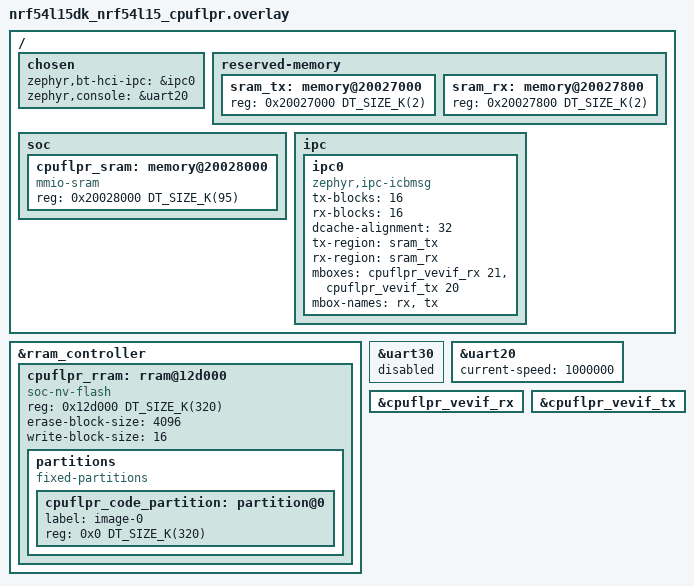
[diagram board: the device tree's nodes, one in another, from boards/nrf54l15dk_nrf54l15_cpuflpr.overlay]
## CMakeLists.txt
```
# SPDX-License-Identifier: Apache-2.0

cmake_minimum_required(VERSION 3.28.0)

find_package(Zephyr REQUIRED HINTS $ENV{ZEPHYR_BASE})
project(hci_ipc)

target_sources(app PRIVATE src/main.c)
```

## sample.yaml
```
sample:
  description: Allows Zephyr to provide Bluetooth connectivity via IPC
  name: Bluetooth HCI IPC
tests:
  sample.bluetooth.hci_ipc:
    harness: bluetooth
    tags: bluetooth
    platform_allow:
      - nrf5340dk/nrf5340/cpunet
      - nrf5340_audio_dk/nrf5340/cpunet
      - nrf5340bsim/nrf5340/cpunet
      - nrf54l15dk/nrf54l15/cpuflpr
    integration_platforms:
      - nrf5340dk/nrf5340/cpunet
      - nrf5340_audio_dk/nrf5340/cpunet
      - nrf54l15dk/nrf54l15/cpuflpr
  sample.bluetooth.hci_ipc.iso_broadcast.bt_ll_sw_split:
    harness: bluetooth
    tags: bluetooth
    extra_args: CONF_FILE="nrf5340_cpunet_iso_broadcast-bt_ll_sw_split.conf"
    platform_allow:
      - nrf5340dk/nrf5340/cpunet
      - nrf5340_audio_dk/nrf5340/cpunet
      - nrf5340bsim/nrf5340/cpunet
    integration_platforms:
      - nrf5340dk/nrf5340/cpunet
  sample.bluetooth.hci_ipc.iso_receive.bt_ll_sw_split:
    harness: bluetooth
    tags: bluetooth
    extra_args: CONF_FILE="nrf5340_cpunet_iso_receive-bt_ll_sw_split.conf"
    platform_allow:
      - nrf5340dk/nrf5340/cpunet
      - nrf5340_audio_dk/nrf5340/cpunet
      - nrf5340bsim/nrf5340/cpunet
    integration_platforms:
      - nrf5340dk/nrf5340/cpunet
  sample.bluetooth.hci_ipc.bis.bt_ll_sw_split:
    harness: bluetooth
    tags: bluetooth
    extra_args: CONF_FILE="nrf5340_cpunet_bis-bt_ll_sw_split.conf"
    platform_allow:
      - nrf5340dk/nrf5340/cpunet
      - nrf5340_audio_dk/nrf5340/cpunet
      - nrf5340bsim/nrf5340/cpunet
    integration_platforms:
      - nrf5340dk/nrf5340/cpunet
  sample.bluetooth.hci_ipc.iso_central.bt_ll_sw_split:
    harness: bluetooth
    tags: bluetooth
    extra_args: CONF_FILE="nrf5340_cpunet_iso_central-bt_ll_sw_split.conf"
    platform_allow:
      - nrf5340dk/nrf5340/cpunet
      - nrf5340_audio_dk/nrf5340/cpunet
      - nrf5340bsim/nrf5340/cpunet
    integration_platforms:
      - nrf5340dk/nrf5340/cpunet
  sample.bluetooth.hci_ipc.iso_peripheral.bt_ll_sw_split:
    harness: bluetooth
    tags: bluetooth
    extra_args: CONF_FILE="nrf5340_cpunet_iso_peripheral-bt_ll_sw_split.conf"
    platform_allow:
      - nrf5340dk/nrf5340/cpunet
      - nrf5340_audio_dk/nrf5340/cpunet
      - nrf5340bsim/nrf5340/cpunet
    integration_platforms:
      - nrf5340dk/nrf5340/cpunet
  sample.bluetooth.hci_ipc.cis.bt_ll_sw_split:
    harness: bluetooth
    tags: bluetooth
    extra_args: CONF_FILE="nrf5340_cpunet_cis-bt_ll_sw_split.conf"
    platform_allow:
      - nrf5340dk/nrf5340/cpunet
      - nrf5340_audio_dk/nrf5340/cpunet
      - nrf5340bsim/nrf5340/cpunet
    integration_platforms:
      - nrf5340dk/nrf5340/cpunet
  sample.bluetooth.hci_ipc.iso.bt_ll_sw_split:
    harness: bluetooth
    tags: bluetooth
    extra_args: CONF_FILE="nrf5340_cpunet_iso-bt_ll_sw_split.conf"
    platform_allow:
      - nrf5340dk/nrf5340/cpunet
      - nrf5340_audio_dk/nrf5340/cpunet
      - nrf5340bsim/nrf5340/cpunet
    integration_platforms:
      - nrf5340dk/nrf5340/cpunet
  sample.bluetooth.hci_ipc.iso.fem.bt_ll_sw_split:
    harness: bluetooth
    tags: bluetooth
    extra_args:
      - CONF_FILE="nrf5340_cpunet_iso-bt_ll_sw_split.conf"
      - EXTRA_CONF_FILE="overlay-nrf5340_cpunet_iso_nrf21540_ek-bt_ll_sw_split.conf"
      - DTC_OVERLAY_FILE="./boards/nrf5340_audio_dk_nrf5340_cpunet_nrf21540_ek.overlay"
    platform_allow:
      - nrf5340_audio_dk/nrf5340/cpunet
    integration_platforms:
      - nrf5340_audio_dk/nrf5340/cpunet
  sample.bluetooth.hci_ipc.df.bt_ll_sw_split:
    harness: bluetooth
    tags: bluetooth
    extra_args:
      - CONF_FILE="nrf5340_cpunet_df-bt_ll_sw_split.conf"
      - DTC_OVERLAY_FILE="nrf5340_cpunet_df-bt_ll_sw_split.overlay"
    platform_allow: nrf5340dk/nrf5340/cpunet
    integration_platforms:
      - nrf5340dk/nrf5340/cpunet
  sample.bluetooth.hci_ipc.df.no_phy_coded.bt_ll_sw_split:
    harness: bluetooth
    tags: bluetooth
    extra_args:
      - CONF_FILE="nrf5340_cpunet_df-bt_ll_sw_split.conf"
      - DTC_OVERLAY_FILE="nrf5340_cpunet_df-bt_ll_sw_split.overlay"
      - CONFIG_BT_CTLR_PHY_CODED=n
    platform_allow: nrf5340dk/nrf5340/cpunet
    integration_platforms:
      - nrf5340dk/nrf5340/cpunet
  sample.bluetooth.hci_ipc.mesh.bt_ll_sw_split:
    harness: bluetooth
    tags: bluetooth
    extra_args: CONF_FILE="nrf5340_cpunet_bt_mesh-bt_ll_sw_split.conf"
    platform_allow: nrf5340dk/nrf5340/cpunet
    integration_platforms:
      - nrf5340dk/nrf5340/cpunet
```

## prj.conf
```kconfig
CONFIG_IPC_SERVICE=y
CONFIG_MBOX=y

CONFIG_HEAP_MEM_POOL_SIZE=4096

CONFIG_MAIN_STACK_SIZE=512
CONFIG_SYSTEM_WORKQUEUE_STACK_MIN_SIZE_APP=512

CONFIG_BT=y
CONFIG_BT_HCI_RAW=y
CONFIG_BT_MAX_CONN=16

# Enable and adjust the below value as necessary to match Controller values
# CONFIG_BT_BUF_EVT_RX_COUNT=16
# CONFIG_BT_BUF_EVT_RX_SIZE=255
# CONFIG_BT_BUF_ACL_RX_SIZE=255
# CONFIG_BT_BUF_ACL_TX_SIZE=251
# CONFIG_BT_BUF_CMD_TX_SIZE=255
```

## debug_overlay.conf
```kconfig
CONFIG_LOG=y

CONFIG_ASSERT=y
CONFIG_EXCEPTION_STACK_TRACE=y
```

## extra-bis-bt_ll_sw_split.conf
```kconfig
# Zephyr Controller stack sizes across supported SoCs
CONFIG_ISR_STACK_SIZE=1536
CONFIG_IDLE_STACK_SIZE=256
CONFIG_MAIN_STACK_SIZE=512
CONFIG_SYSTEM_WORKQUEUE_STACK_SIZE=512
CONFIG_HEAP_MEM_POOL_SIZE=4096

# BT Buffers
CONFIG_BT_BUF_EVT_RX_COUNT=16
CONFIG_BT_BUF_EVT_RX_SIZE=255
CONFIG_BT_BUF_ACL_RX_SIZE=255
CONFIG_BT_BUF_ACL_TX_SIZE=251
CONFIG_BT_BUF_CMD_TX_SIZE=255

# Host and Controller common dependencies
CONFIG_BT_BROADCASTER=y
CONFIG_BT_OBSERVER=y
CONFIG_BT_EXT_ADV=y
CONFIG_BT_PER_ADV=y
CONFIG_BT_PER_ADV_SYNC=y
CONFIG_BT_PER_ADV_SYNC_MAX=2
CONFIG_BT_CENTRAL=y
CONFIG_BT_PERIPHERAL=y
CONFIG_BT_MAX_CONN=2

# Broadcast and Connected ISO
CONFIG_BT_ISO_BROADCASTER=y
CONFIG_BT_ISO_SYNC_RECEIVER=y
CONFIG_BT_ISO_CENTRAL=n
CONFIG_BT_ISO_PERIPHERAL=n

# ISO Streams
CONFIG_BT_ISO_MAX_CHAN=4
# In theory, CONFIG_BT_ISO_TX_BUF_COUNT=1, should be sufficient but this count
# is used in the context of IPC which falls into a "Newton's Cradle" effect
# where probably (CONFIG_BT_CTLR_ISO_TX_BUFFERS - CONFIG_BT_ISO_TX_BUF_COUNT)
# buffers get throttled. Hence, always have the value equal or greater.
CONFIG_BT_ISO_TX_BUF_COUNT=12
CONFIG_BT_ISO_RX_BUF_COUNT=1

# Controller
CONFIG_BT_LL_SW_SPLIT=y
CONFIG_BT_CTLR_DTM_HCI=y
CONFIG_BT_CTLR_ASSERT_HANDLER=y
CONFIG_BT_HCI_VS_FATAL_ERROR=y

# Rx ACL and Adv Reports
CONFIG_BT_CTLR_RX_BUFFERS=9
CONFIG_BT_CTLR_DATA_LENGTH_MAX=251

# Coded PHY support
CONFIG_BT_CTLR_PHY_CODED=y

# Advertising Sets and Extended Scanning
CONFIG_BT_CTLR_ADV_EXT=y
CONFIG_BT_CTLR_ADV_SET=3
CONFIG_BT_CTLR_ADV_DATA_LEN_MAX=191
CONFIG_BT_CTLR_SCAN_DATA_LEN_MAX=1650

CONFIG_BT_CTLR_ADVANCED_FEATURES=y
CONFIG_BT_CTLR_ADV_AUX_SET=3
CONFIG_BT_CTLR_ADV_AUX_PDU_BACK2BACK=y
CONFIG_BT_CTLR_ADV_SYNC_SET=3
CONFIG_BT_CTLR_ADV_SYNC_PDU_BACK2BACK=y
CONFIG_BT_CTLR_ADV_DATA_BUF_MAX=6

# Increase the below to receive interleaved advertising chains
CONFIG_BT_CTLR_SCAN_AUX_SET=3
CONFIG_BT_CTLR_LOW_LAT_ULL=y
# CONFIG_BT_CTLR_SCAN_AUX_USE_CHAINS=y
# CONFIG_BT_CTLR_SCAN_AUX_CHAIN_COUNT=3

CONFIG_BT_CTLR_ADV_RESERVE_MAX=n
CONFIG_BT_CTLR_ADV_ISO_RESERVE_MAX=y
CONFIG_BT_CTLR_SCAN_AUX_SYNC_RESERVE_MIN=y
CONFIG_BT_CTLR_SYNC_PERIODIC_SKIP_ON_SCAN_AUX=n
CONFIG_BT_CTLR_SYNC_ISO_RESERVE_MAX=n
CONFIG_BT_CTLR_CENTRAL_RESERVE_MAX=n
CONFIG_BT_CTLR_PERIPHERAL_RESERVE_MAX=n
CONFIG_BT_CTLR_PERIPHERAL_ISO_RESERVE_MAX=n
CONFIG_BT_CTLR_EVENT_OVERHEAD_RESERVE_MAX=y
CONFIG_BT_CTLR_SLOT_RESERVATION_UPDATE=n
CONFIG_BT_CTLR_SCAN_UNRESERVED=y
CONFIG_BT_TICKER_NEXT_SLOT_GET_MATCH=y
CONFIG_BT_TICKER_EXT=y
CONFIG_BT_TICKER_EXT_SLOT_WINDOW_YIELD=y

# Control Procedure
CONFIG_BT_CTLR_LLCP_LOCAL_PROC_CTX_BUF_NUM=6

# ISO Broadcaster Controller
CONFIG_BT_CTLR_ADV_EXT=y
CONFIG_BT_CTLR_ADV_PERIODIC=y
CONFIG_BT_CTLR_SYNC_TRANSFER_SENDER=y
CONFIG_BT_CTLR_ADV_ISO=y
CONFIG_BT_CTLR_ADV_ISO_SEQUENTIAL=y
CONFIG_BT_CTLR_ADV_ISO_INTERLEAVED=y
CONFIG_BT_CTLR_ADV_ISO_SET=2
CONFIG_BT_CTLR_ADV_ISO_STREAM_COUNT=4
CONFIG_BT_CTLR_ADV_ISO_STREAM_MAX=2
CONFIG_BT_CTLR_ADV_ISO_PDU_LEN_MAX=247

# ISO Receive Controller
CONFIG_BT_CTLR_ADV_EXT=y
CONFIG_BT_CTLR_SYNC_PERIODIC=y
CONFIG_BT_CTLR_SYNC_TRANSFER_RECEIVER=y
CONFIG_BT_CTLR_SYNC_ISO=y
CONFIG_BT_CTLR_SYNC_ISO_SEQUENTIAL=y
CONFIG_BT_CTLR_SYNC_ISO_INTERLEAVED=y
CONFIG_BT_CTLR_SCAN_SYNC_ISO_SET=1
CONFIG_BT_CTLR_SYNC_ISO_STREAM_COUNT=2
CONFIG_BT_CTLR_SYNC_ISO_STREAM_MAX=2
CONFIG_BT_CTLR_SYNC_ISO_PDU_LEN_MAX=251

# ISO Transmissions
CONFIG_BT_CTLR_ISOAL_SOURCES=4
CONFIG_BT_CTLR_ISO_TX_BUFFERS=12
CONFIG_BT_CTLR_ISO_TX_BUFFER_SIZE=255
CONFIG_BT_CTLR_ISO_TX_SDU_LEN_MAX=247

# ISO Receptions
CONFIG_BT_CTLR_ISOAL_SINKS=2
CONFIG_BT_CTLR_ISO_RX_BUFFERS=4
```

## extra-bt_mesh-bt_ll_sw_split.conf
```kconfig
# Zephyr Controller stack sizes across supported SoCs
CONFIG_ISR_STACK_SIZE=1536
CONFIG_IDLE_STACK_SIZE=256
CONFIG_MAIN_STACK_SIZE=512
CONFIG_SYSTEM_WORKQUEUE_STACK_SIZE=512
CONFIG_HEAP_MEM_POOL_SIZE=4096

# Controller
CONFIG_BT_LL_SW_SPLIT=y
CONFIG_BT_CTLR_ASSERT_HANDLER=y
CONFIG_BT_HCI_VS_FATAL_ERROR=y

# Disable unused Bluetooth features
CONFIG_BT_CTLR_DUP_FILTER_LEN=0
CONFIG_BT_CTLR_LE_ENC=n
CONFIG_BT_CTLR_LE_PING=n
CONFIG_BT_DATA_LEN_UPDATE=n
CONFIG_BT_PHY_UPDATE=n
CONFIG_BT_CTLR_MIN_USED_CHAN=n
CONFIG_BT_CTLR_PRIVACY=n

CONFIG_BT_OBSERVER=y
CONFIG_BT_BROADCASTER=y
CONFIG_BT_EXT_ADV=y
```

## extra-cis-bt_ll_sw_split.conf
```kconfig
# Zephyr Controller stack sizes across supported SoCs
CONFIG_ISR_STACK_SIZE=1536
CONFIG_IDLE_STACK_SIZE=256
CONFIG_MAIN_STACK_SIZE=512
CONFIG_SYSTEM_WORKQUEUE_STACK_SIZE=512
CONFIG_HEAP_MEM_POOL_SIZE=4096

# BT Buffers
CONFIG_BT_BUF_EVT_RX_COUNT=16
CONFIG_BT_BUF_EVT_RX_SIZE=255
CONFIG_BT_BUF_ACL_RX_SIZE=255
CONFIG_BT_BUF_ACL_TX_SIZE=251
CONFIG_BT_BUF_CMD_TX_SIZE=255

# Host and Controller common dependencies
CONFIG_BT_BROADCASTER=y
CONFIG_BT_OBSERVER=y
CONFIG_BT_EXT_ADV=y
CONFIG_BT_PER_ADV=n
CONFIG_BT_PER_ADV_SYNC=n
CONFIG_BT_CENTRAL=y
CONFIG_BT_PERIPHERAL=y
CONFIG_BT_MAX_CONN=3

# Broadcast and Connected ISO
CONFIG_BT_ISO_BROADCASTER=n
CONFIG_BT_ISO_SYNC_RECEIVER=n
CONFIG_BT_ISO_CENTRAL=y
CONFIG_BT_ISO_PERIPHERAL=y

# ISO Streams
CONFIG_BT_ISO_MAX_CHAN=4
# In theory, CONFIG_BT_ISO_TX_BUF_COUNT=1, should be sufficient but this count
# is used in the context of IPC which falls into a "Newton's Cradle" effect
# where probably (CONFIG_BT_CTLR_ISO_TX_BUFFERS - CONFIG_BT_ISO_TX_BUF_COUNT)
# buffers get throttled. Hence, always have the value equal or greater.
CONFIG_BT_ISO_TX_BUF_COUNT=6
CONFIG_BT_ISO_RX_BUF_COUNT=1

# Controller
CONFIG_BT_LL_SW_SPLIT=y
CONFIG_BT_CTLR_DTM_HCI=y
CONFIG_BT_CTLR_ASSERT_HANDLER=y
CONFIG_BT_HCI_VS_FATAL_ERROR=y

# Rx ACL and Adv Reports
CONFIG_BT_CTLR_RX_BUFFERS=9
CONFIG_BT_CTLR_DATA_LENGTH_MAX=251

# Coded PHY support
CONFIG_BT_CTLR_PHY_CODED=y

# Advertising Sets and Extended Scanning
CONFIG_BT_CTLR_ADV_EXT=y
CONFIG_BT_CTLR_ADV_SET=3
CONFIG_BT_CTLR_ADV_DATA_LEN_MAX=191
CONFIG_BT_CTLR_SCAN_DATA_LEN_MAX=1650

CONFIG_BT_CTLR_ADVANCED_FEATURES=y
CONFIG_BT_CTLR_ADV_AUX_SET=3
CONFIG_BT_CTLR_ADV_AUX_PDU_BACK2BACK=y
CONFIG_BT_CTLR_ADV_DATA_BUF_MAX=6

# Increase the below to receive interleaved advertising chains
CONFIG_BT_CTLR_SCAN_AUX_SET=3
CONFIG_BT_CTLR_LOW_LAT_ULL=y
# CONFIG_BT_CTLR_SCAN_AUX_USE_CHAINS=y
# CONFIG_BT_CTLR_SCAN_AUX_CHAIN_COUNT=3

CONFIG_BT_CTLR_ADV_RESERVE_MAX=n
CONFIG_BT_CTLR_SCAN_AUX_SYNC_RESERVE_MIN=y
CONFIG_BT_CTLR_SYNC_PERIODIC_SKIP_ON_SCAN_AUX=n
CONFIG_BT_CTLR_CENTRAL_RESERVE_MAX=n
CONFIG_BT_CTLR_PERIPHERAL_RESERVE_MAX=n
CONFIG_BT_CTLR_EVENT_OVERHEAD_RESERVE_MAX=y
CONFIG_BT_CTLR_SLOT_RESERVATION_UPDATE=n
CONFIG_BT_CTLR_SCAN_UNRESERVED=y
CONFIG_BT_TICKER_NEXT_SLOT_GET_MATCH=y
CONFIG_BT_TICKER_EXT=y
CONFIG_BT_TICKER_EXT_SLOT_WINDOW_YIELD=y

# Control Procedure
CONFIG_BT_CTLR_LLCP_LOCAL_PROC_CTX_BUF_NUM=6

# ISO Connection Oriented
CONFIG_BT_CTLR_CENTRAL_ISO=y
CONFIG_BT_CTLR_PERIPHERAL_ISO=y
CONFIG_BT_CTLR_CONN_ISO_GROUPS=1
CONFIG_BT_CTLR_CONN_ISO_STREAMS=2
CONFIG_BT_CTLR_CONN_ISO_STREAMS_PER_GROUP=2
CONFIG_BT_CTLR_CONN_ISO_PDU_LEN_MAX=251
CONFIG_BT_CTLR_CONN_ISO_LOW_LATENCY_POLICY=y

# ISO Transmissions
CONFIG_BT_CTLR_ISOAL_SOURCES=2
CONFIG_BT_CTLR_ISO_TX_BUFFERS=6
CONFIG_BT_CTLR_ISO_TX_BUFFER_SIZE=255
CONFIG_BT_CTLR_ISO_TX_SDU_LEN_MAX=247

# ISO Receptions
CONFIG_BT_CTLR_ISOAL_SINKS=2
CONFIG_BT_CTLR_ISO_RX_BUFFERS=4
```

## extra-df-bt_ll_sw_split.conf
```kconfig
# Zephyr Controller stack sizes across supported SoCs
CONFIG_ISR_STACK_SIZE=1536
CONFIG_IDLE_STACK_SIZE=256
CONFIG_MAIN_STACK_SIZE=512
CONFIG_SYSTEM_WORKQUEUE_STACK_SIZE=512
CONFIG_HEAP_MEM_POOL_SIZE=4096

# BT Buffers
CONFIG_BT_BUF_EVT_RX_COUNT=16
CONFIG_BT_BUF_EVT_RX_SIZE=255
CONFIG_BT_BUF_ACL_RX_SIZE=255
CONFIG_BT_BUF_ACL_TX_SIZE=251
CONFIG_BT_BUF_CMD_TX_SIZE=255

# Host and Controller common dependencies
CONFIG_BT_BROADCASTER=y
CONFIG_BT_OBSERVER=y
CONFIG_BT_EXT_ADV=y
CONFIG_BT_PER_ADV=y
CONFIG_BT_PER_ADV_SYNC=y
CONFIG_BT_PER_ADV_SYNC_MAX=2
CONFIG_BT_CENTRAL=y
CONFIG_BT_PERIPHERAL=y
CONFIG_BT_MAX_CONN=2

# Controller
CONFIG_BT_LL_SW_SPLIT=y
CONFIG_BT_CTLR_DTM_HCI=y
CONFIG_BT_CTLR_ASSERT_HANDLER=y
CONFIG_BT_HCI_VS_FATAL_ERROR=y

# Rx ACL and Adv Reports
CONFIG_BT_CTLR_RX_BUFFERS=9
CONFIG_BT_CTLR_DATA_LENGTH_MAX=251

# Coded PHY support
CONFIG_BT_CTLR_PHY_CODED=y

# Advertising Sets and Extended Scanning
CONFIG_BT_CTLR_ADV_EXT=y
CONFIG_BT_CTLR_ADV_SET=3
CONFIG_BT_CTLR_ADV_DATA_LEN_MAX=191
CONFIG_BT_CTLR_SCAN_DATA_LEN_MAX=1650

CONFIG_BT_CTLR_ADVANCED_FEATURES=y
CONFIG_BT_CTLR_ADV_AUX_SET=3
CONFIG_BT_CTLR_ADV_AUX_PDU_BACK2BACK=y
CONFIG_BT_CTLR_ADV_SYNC_SET=3
CONFIG_BT_CTLR_ADV_SYNC_PDU_BACK2BACK=y
CONFIG_BT_CTLR_ADV_DATA_BUF_MAX=6

# Increase the below to receive interleaved advertising chains
CONFIG_BT_CTLR_SCAN_AUX_SET=1
CONFIG_BT_CTLR_LOW_LAT_ULL=y
# CONFIG_BT_CTLR_SCAN_AUX_USE_CHAINS=y
# CONFIG_BT_CTLR_SCAN_AUX_CHAIN_COUNT=1

CONFIG_BT_CTLR_SCAN_UNRESERVED=y
CONFIG_BT_TICKER_NEXT_SLOT_GET_MATCH=y

# Control Procedure
CONFIG_BT_CTLR_LLCP_LOCAL_PROC_CTX_BUF_NUM=6

# Direction Finding
CONFIG_BT_CTLR_DF=y
CONFIG_BT_CTLR_DF_PER_ADV_CTE_NUM_MAX=3
CONFIG_BT_CTLR_DF_PER_SCAN_CTE_NUM_MAX=3

# Direction Finding Tx
CONFIG_BT_CTLR_DF_CTE_TX=y
CONFIG_BT_CTLR_DF_CONN_CTE_TX=y
CONFIG_BT_CTLR_DF_ANT_SWITCH_TX=y
CONFIG_BT_CTLR_DF_CONN_CTE_RSP=y

# Direction Finding Rx
CONFIG_BT_CTLR_DF_CTE_RX=y
CONFIG_BT_CTLR_DF_CONN_CTE_RX=y
CONFIG_BT_CTLR_DF_ANT_SWITCH_RX=y
CONFIG_BT_CTLR_DF_CONN_CTE_REQ=y
```

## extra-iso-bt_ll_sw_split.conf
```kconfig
# Zephyr Controller stack sizes across supported SoCs
# Board specific values can be present in the sample
# Example, nRF54H20 needs > 1.5 KB main stack to support PSA Crypto? and 1.5 KB ISR Stack?
# CONFIG_MAIN_STACK_SIZE=512
# CONFIG_ISR_STACK_SIZE=1536
CONFIG_IDLE_STACK_SIZE=256
CONFIG_SYSTEM_WORKQUEUE_STACK_SIZE=512
CONFIG_HEAP_MEM_POOL_SIZE=4096

# picolib, reduce the size of the printf code by switching to the version without 64-bit integer
# support.
CONFIG_CBPRINTF_REDUCED_INTEGRAL=y

# Use link time optimization for code size reduction
CONFIG_ISR_TABLES_LOCAL_DECLARATION=y
CONFIG_LTO=y

# Generate .lst file, to find HCI h/w error event given PC
CONFIG_OUTPUT_DISASSEMBLY=y
CONFIG_OUTPUT_DISASSEMBLY_WITH_SOURCE=y

# BT Buffers
CONFIG_BT_BUF_CMD_TX_SIZE=255
CONFIG_BT_BUF_EVT_RX_COUNT=16
CONFIG_BT_BUF_EVT_RX_SIZE=255
CONFIG_BT_BUF_ACL_TX_COUNT=3
CONFIG_BT_BUF_ACL_TX_SIZE=251
CONFIG_BT_BUF_ACL_RX_COUNT_EXTRA=1
CONFIG_BT_BUF_ACL_RX_SIZE=255

# Host and Controller common dependencies
CONFIG_BT_BROADCASTER=y
CONFIG_BT_OBSERVER=y
CONFIG_BT_EXT_ADV=y
CONFIG_BT_PER_ADV=y
CONFIG_BT_PER_ADV_SYNC=y
CONFIG_BT_PER_ADV_SYNC_MAX=2
CONFIG_BT_CENTRAL=y
CONFIG_BT_PERIPHERAL=y
CONFIG_BT_MAX_CONN=3

# Broadcast and Connected ISO
CONFIG_BT_ISO_BROADCASTER=y
CONFIG_BT_ISO_SYNC_RECEIVER=y
CONFIG_BT_ISO_CENTRAL=y
CONFIG_BT_ISO_PERIPHERAL=y

# ISO Streams
CONFIG_BT_ISO_TX_MTU=310
CONFIG_BT_ISO_RX_MTU=310
CONFIG_BT_ISO_MAX_CHAN=4
# In theory, CONFIG_BT_ISO_TX_BUF_COUNT=1, should be sufficient but this count
# is used in the context of IPC which falls into a "Newton's Cradle" effect
# where probably (CONFIG_BT_CTLR_ISO_TX_BUFFERS - CONFIG_BT_ISO_TX_BUF_COUNT)
# buffers get throttled. Hence, always have the value equal or greater.
CONFIG_BT_ISO_TX_BUF_COUNT=12
CONFIG_BT_ISO_RX_BUF_COUNT=1

# Controller
CONFIG_BT_LL_SW_SPLIT=y
CONFIG_BT_CTLR_DTM_HCI=y
CONFIG_BT_CTLR_ASSERT_HANDLER=y
CONFIG_BT_HCI_VS_FATAL_ERROR=y

# Rx ACL and Adv Reports
CONFIG_BT_CTLR_RX_BUFFERS=9
CONFIG_BT_CTLR_DATA_LENGTH_MAX=251

# Coded PHY support
CONFIG_BT_CTLR_PHY_CODED=y

# Advertising Sets and Extended Scanning
CONFIG_BT_CTLR_ADV_EXT=y
CONFIG_BT_CTLR_ADV_SET=3
CONFIG_BT_CTLR_ADV_DATA_LEN_MAX=191
CONFIG_BT_CTLR_SCAN_DATA_LEN_MAX=1650

CONFIG_BT_CTLR_ADVANCED_FEATURES=y
CONFIG_BT_CTLR_ADV_AUX_SET=3
CONFIG_BT_CTLR_ADV_AUX_PDU_BACK2BACK=y
CONFIG_BT_CTLR_ADV_SYNC_SET=3
CONFIG_BT_CTLR_ADV_SYNC_PDU_BACK2BACK=y
CONFIG_BT_CTLR_ADV_DATA_BUF_MAX=6

# Increase the below to receive interleaved advertising chains
CONFIG_BT_CTLR_SCAN_AUX_SET=3
CONFIG_BT_CTLR_LOW_LAT_ULL=y
# CONFIG_BT_CTLR_SCAN_AUX_USE_CHAINS=y
# CONFIG_BT_CTLR_SCAN_AUX_CHAIN_COUNT=3

CONFIG_BT_CTLR_DUP_FILTER_LEN=8

CONFIG_BT_CTLR_ADV_RESERVE_MAX=n
CONFIG_BT_CTLR_ADV_ISO_RESERVE_MAX=y
CONFIG_BT_CTLR_SCAN_AUX_SYNC_RESERVE_MIN=y
CONFIG_BT_CTLR_SYNC_PERIODIC_SKIP_ON_SCAN_AUX=n
CONFIG_BT_CTLR_SYNC_ISO_RESERVE_MAX=n
CONFIG_BT_CTLR_CENTRAL_RESERVE_MAX=n
CONFIG_BT_CTLR_PERIPHERAL_RESERVE_MAX=n
CONFIG_BT_CTLR_PERIPHERAL_ISO_RESERVE_MAX=n
CONFIG_BT_CTLR_EVENT_OVERHEAD_RESERVE_MAX=y
CONFIG_BT_CTLR_SLOT_RESERVATION_UPDATE=n
CONFIG_BT_CTLR_SCAN_UNRESERVED=y
CONFIG_BT_TICKER_NEXT_SLOT_GET_MATCH=y
CONFIG_BT_TICKER_EXT=y
CONFIG_BT_TICKER_EXT_SLOT_WINDOW_YIELD=y

# Control Procedure
CONFIG_BT_CTLR_LLCP_LOCAL_PROC_CTX_BUF_NUM=6

# ISO Broadcaster Controller
CONFIG_BT_CTLR_ADV_EXT=y
CONFIG_BT_CTLR_ADV_PERIODIC=y
CONFIG_BT_CTLR_SYNC_TRANSFER_SENDER=y
CONFIG_BT_CTLR_ADV_ISO=y
CONFIG_BT_CTLR_ADV_ISO_SEQUENTIAL=y
CONFIG_BT_CTLR_ADV_ISO_INTERLEAVED=y
CONFIG_BT_CTLR_ADV_ISO_SET=2
CONFIG_BT_CTLR_ADV_ISO_STREAM_COUNT=4
CONFIG_BT_CTLR_ADV_ISO_STREAM_MAX=2
CONFIG_BT_CTLR_ADV_ISO_PDU_LEN_MAX=247

# ISO Receive Controller
CONFIG_BT_CTLR_ADV_EXT=y
CONFIG_BT_CTLR_SYNC_PERIODIC=y
CONFIG_BT_CTLR_SYNC_TRANSFER_RECEIVER=y
CONFIG_BT_CTLR_SYNC_ISO=y
CONFIG_BT_CTLR_SYNC_ISO_SEQUENTIAL=y
CONFIG_BT_CTLR_SYNC_ISO_INTERLEAVED=y
CONFIG_BT_CTLR_SCAN_SYNC_ISO_SET=1
CONFIG_BT_CTLR_SYNC_ISO_STREAM_COUNT=2
CONFIG_BT_CTLR_SYNC_ISO_STREAM_MAX=2
CONFIG_BT_CTLR_SYNC_ISO_PDU_LEN_MAX=251

# ISO Connection Oriented
CONFIG_BT_CTLR_CENTRAL_ISO=y
CONFIG_BT_CTLR_PERIPHERAL_ISO=y
CONFIG_BT_CTLR_CONN_ISO_GROUPS=1
CONFIG_BT_CTLR_CONN_ISO_STREAMS=2
CONFIG_BT_CTLR_CONN_ISO_STREAMS_PER_GROUP=2
CONFIG_BT_CTLR_CONN_ISO_PDU_LEN_MAX=251
CONFIG_BT_CTLR_CONN_ISO_LOW_LATENCY_POLICY=y

# ISO Transmissions
CONFIG_BT_CTLR_ISOAL_SOURCES=4
CONFIG_BT_CTLR_ISO_TX_BUFFERS=12
CONFIG_BT_CTLR_ISO_TX_BUFFER_SIZE=255
CONFIG_BT_CTLR_ISO_TX_SDU_LEN_MAX=247

# ISO Receptions
CONFIG_BT_CTLR_ISOAL_SINKS=2
CONFIG_BT_CTLR_ISO_RX_BUFFERS=4

# Tx Power Dynamic Control
CONFIG_BT_CTLR_TX_PWR_DYNAMIC_CONTROL=y

# Ignore HCI ISO data Tx sequence numbers
# CONFIG_BT_CTLR_ISOAL_PSN_IGNORE=y

# The hci_ipc image has a quite high RAM usage so we need to carefully
# tweak Mbed TLS parameters in order to build successfully:
# - use CSPRNG source as random source for PSA. This removes
#   requirement for legacy Mbed TLS entropy+ctr-drbg modules, which
#   saves RAM and ROM;
# - use ROM pre-computed tables for AES;
# - reduce the number of key slots to 3 in the PSA core. This is not a
#   huge limitation since PSA crypto is only used for AES-CMAC in hci_ipc.
#
# Upstream nRF54H20 has no true random number generator driver, lets keep this disabled
# CONFIG_MBEDTLS_PSA_CRYPTO_EXTERNAL_RNG=y
CONFIG_MBEDTLS_AES_ROM_TABLES=y
CONFIG_MBEDTLS_PSA_KEY_SLOT_COUNT=3
```

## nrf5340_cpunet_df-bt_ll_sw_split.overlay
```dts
/*
 * Copyright (c) 2022 Nordic Semiconductor ASA
 *
 * SPDX-License-Identifier: Apache-2.0
 */

&radio {
	/* This is an example number of antennas that may be available
	 * on antenna matrix board.
	 */
	dfe-antenna-num = <10>;
	/* This is an example switch pattern that will be used to set an
	 * antenna for Tx PDU (period before start of Tx CTE).
	 */
	dfe-pdu-antenna = <0x0>;

	/* These are example GPIO pin numbers that are provided to
	 * Radio peripheral. The pins will be acquired by Radio to
	 * drive antenna switching when AoD is enabled.
	 */
	dfegpio0-gpios = <&gpio0 4 0>;
	dfegpio1-gpios = <&gpio0 5 0>;
	dfegpio2-gpios = <&gpio0 6 0>;
	dfegpio3-gpios = <&gpio0 7 0>;
	status = "okay";
};
```

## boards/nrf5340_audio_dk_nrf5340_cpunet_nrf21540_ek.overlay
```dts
/ {
	nrf_radio_fem: nrf21540_fem {
		compatible = "nordic,nrf21540-fem";
		tx-en-gpios = <&arduino_header 11 GPIO_ACTIVE_HIGH>; /* D5 */
		rx-en-gpios = <&arduino_header 9 GPIO_ACTIVE_HIGH>; /* D3 */
		pdn-gpios = <&arduino_header 15 GPIO_ACTIVE_HIGH>; /* D9 */
		ant-sel-gpios = <&arduino_header 10 GPIO_ACTIVE_HIGH>; /* D4 */
		mode-gpios = <&arduino_header 8 GPIO_ACTIVE_HIGH>; /* D2 */
		supply-voltage-mv = <3000>;
	};
};

&radio {
	fem = <&nrf_radio_fem>;
};
```

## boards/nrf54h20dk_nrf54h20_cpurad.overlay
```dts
/*
 * Copyright 2024 Nordic Semiconductor ASA
 *
 * SPDX-License-Identifier: Apache-2.0
 */

/ {
	chosen {
		zephyr,bt-hci-ipc = &ipc0;
	};
};

ipc0: &cpuapp_cpurad_ipc {
	status = "okay";
};

&cpuapp_cpurad_ram0x_region {
	status = "okay";
};

&cpurad_bellboard {
	status = "okay";
};

&cpuapp_bellboard {
	status = "okay";
};
```

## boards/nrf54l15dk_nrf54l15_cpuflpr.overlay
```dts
/*
 * Copyright (c) 2026 Nordic Semiconductor ASA
 *
 * SPDX-License-Identifier: Apache-2.0
 */

/*
 * Must match boards/nrf54l15dk_nrf54l15_cpuapp.overlay of the samples using
 * this image on FLPR.
 *
 * RRAM: 1204 (APP) + 320 (FLPR) = 1524KB
 * RAM:  156 (APP) + 4 (IPC) + 95 (FLPR) + 1 (unused) = 256KB
 */

/delete-node/ &{/soc/reserved-memory};
/delete-node/ &cpuflpr_sram;
/delete-node/ &cpuflpr_rram;

/ {
	chosen {
		zephyr,bt-hci-ipc = &ipc0;
		zephyr,console = &uart20;
	};

	reserved-memory {
		sram_tx: memory@20027000 {
			reg = <0x20027000 DT_SIZE_K(2)>;
		};

		sram_rx: memory@20027800 {
			reg = <0x20027800 DT_SIZE_K(2)>;
		};
	};

	soc {
		cpuflpr_sram: memory@20028000 {
			compatible = "mmio-sram";
			reg = <0x20028000 DT_SIZE_K(95)>;
			ranges = <0x0 0x20028000 DT_SIZE_K(95)>;
			#address-cells = <1>;
			#size-cells = <1>;
		};
	};

	ipc {
		ipc0: ipc0 {
			compatible = "zephyr,ipc-icbmsg";
			tx-blocks = <16>;
			rx-blocks = <16>;
			dcache-alignment = <32>;
			tx-region = <&sram_tx>;
			rx-region = <&sram_rx>;
			mboxes = <&cpuflpr_vevif_rx 21>, <&cpuflpr_vevif_tx 20>;
			mbox-names = "rx", "tx";
			status = "okay";
		};
	};
};

&rram_controller {
	cpuflpr_rram: rram@12d000 {
		compatible = "soc-nv-flash";
		reg = <0x12d000 DT_SIZE_K(320)>;
		ranges = <0x0 0x12d000 DT_SIZE_K(320)>;
		erase-block-size = <4096>;
		write-block-size = <16>;
		#address-cells = <1>;
		#size-cells = <1>;

		partitions {
			compatible = "fixed-partitions";
			#address-cells = <1>;
			#size-cells = <1>;
			ranges;

			cpuflpr_code_partition: partition@0 {
				label = "image-0";
				reg = <0x0 DT_SIZE_K(320)>;
			};
		};
	};
};

&uart30 {
	status = "disabled";
};

&uart20 {
	current-speed = <1000000>;
	status = "okay";
};

&cpuflpr_vevif_rx {
	status = "okay";
};

&cpuflpr_vevif_tx {
	status = "okay";
};
```

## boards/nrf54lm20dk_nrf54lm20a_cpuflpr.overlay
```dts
/*
 * Copyright (c) 2026 Nordic Semiconductor ASA
 *
 * SPDX-License-Identifier: Apache-2.0
 */

/ {
	chosen {
		zephyr,bt-hci-ipc = &ipc0;
		zephyr,console = &uart20;
	};

	soc {
		reserved-memory {
			#address-cells = <1>;
			#size-cells = <1>;

			sram_tx: memory@2001f800 {
				reg = <0x2001f800 DT_SIZE_K(1)>;
			};

			sram_rx: memory@2001fc00 {
				reg = <0x2001fc00 DT_SIZE_K(1)>;
			};
		};
	};

	ipc {
		ipc0: ipc0 {
			compatible = "zephyr,ipc-icbmsg";
			tx-blocks = <16>;
			rx-blocks = <16>;
			dcache-alignment = <32>;
			tx-region = <&sram_tx>;
			rx-region = <&sram_rx>;
			mboxes = <&cpuflpr_vevif_rx 21>, <&cpuflpr_vevif_tx 20>;
			mbox-names = "rx", "tx";
			status = "okay";
		};
	};
};

&cpuflpr_sram {
	reg = <0x20020000 DT_SIZE_K(127)>;
	ranges = <0x0 0x20020000 DT_SIZE_K(127)>;
};

&cpuflpr_rram {
	reg = <0x120000 DT_SIZE_K(384)>;
	ranges = <0x0 0x120000 DT_SIZE_K(384)>;

	partitions {
		compatible = "fixed-partitions";
		#address-cells = <1>;
		#size-cells = <1>;
		ranges;

		cpuflpr_code_partition: partition@0 {
			label = "image-0";
			reg = <0x0 DT_SIZE_K(384)>;
		};
	};
};

&uart30 {
	status = "disabled";
};

&uart20 {
	current-speed = <1000000>;
	status = "okay";
};

&cpuflpr_vevif_rx {
	status = "okay";
};

&cpuflpr_vevif_tx {
	status = "okay";
};
```

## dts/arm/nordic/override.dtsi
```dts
/* Keep default IRQ priority low for peripherals to reduce Radio ISR latency.
 * ARM Cortex-M4 lowest priority value of 5, i.e. considering Zephyr reserved 2
 * levels for Exceptions and ZLI (if enabled).
 */
#define NRF_DEFAULT_IRQ_PRIORITY 5
```

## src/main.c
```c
/*
 * Copyright (c) 2019-2021 Nordic Semiconductor ASA
 *
 * SPDX-License-Identifier: Apache-2.0
 */

#include <errno.h>
#include <stddef.h>
#include <stdio.h>
#include <string.h>

#include <zephyr/device.h>
#include <zephyr/kernel.h>
#include <zephyr/sys/byteorder.h>
#include <zephyr/sys/util.h>

#include <zephyr/ipc/ipc_service.h>

#include <zephyr/net_buf.h>
#include <zephyr/bluetooth/bluetooth.h>
#include <zephyr/bluetooth/l2cap.h>
#include <zephyr/bluetooth/hci.h>
#include <zephyr/bluetooth/buf.h>
#include <zephyr/bluetooth/hci_raw.h>
#include <zephyr/bluetooth/hci_vs.h>

#include <zephyr/logging/log_ctrl.h>
#include <zephyr/logging/log.h>

LOG_MODULE_REGISTER(hci_ipc, CONFIG_BT_LOG_LEVEL);

BUILD_ASSERT(!IS_ENABLED(CONFIG_BT_CONN) || IS_ENABLED(CONFIG_BT_HCI_ACL_FLOW_CONTROL),
	     "HCI IPC driver can drop ACL data without Controller-to-Host ACL flow control");

static struct ipc_ept hci_ept;

static K_THREAD_STACK_DEFINE(tx_thread_stack, CONFIG_BT_HCI_TX_STACK_SIZE);
static struct k_thread tx_thread_data;
static K_FIFO_DEFINE(tx_queue);
static K_SEM_DEFINE(ipc_bound_sem, 0, 1);
#if defined(CONFIG_BT_CTLR_ASSERT_HANDLER) || defined(CONFIG_BT_HCI_VS_FATAL_ERROR)
/* A flag used to store information if the IPC endpoint has already been bound. The end point can't
 * be used before that happens.
 */
static bool ipc_ept_ready;
#endif /* CONFIG_BT_CTLR_ASSERT_HANDLER || CONFIG_BT_HCI_VS_FATAL_ERROR */

#define HCI_IPC_CMD 0x01
#define HCI_IPC_ACL 0x02
#define HCI_IPC_SCO 0x03
#define HCI_IPC_EVT 0x04
#define HCI_IPC_ISO 0x05

#define HCI_FATAL_ERR_MSG true
#define HCI_REGULAR_MSG false

static struct net_buf *hci_ipc_cmd_recv(uint8_t *data, size_t remaining)
{
	struct bt_hci_cmd_hdr *hdr = (void *)data;
	struct net_buf *buf;

	if (remaining < sizeof(*hdr)) {
		LOG_ERR("Not enough data for command header");
		return NULL;
	}

	buf = bt_buf_get_tx(BT_BUF_CMD, K_NO_WAIT, hdr, sizeof(*hdr));
	if (buf) {
		data += sizeof(*hdr);
		remaining -= sizeof(*hdr);
	} else {
		LOG_ERR("No available command buffers!");
		return NULL;
	}

	if (remaining != hdr->param_len) {
		LOG_ERR("Command payload length is not correct");
		net_buf_unref(buf);
		return NULL;
	}

	if (remaining > net_buf_tailroom(buf)) {
		LOG_ERR("Not enough space in buffer");
		net_buf_unref(buf);
		return NULL;
	}

	LOG_DBG("len %u", hdr->param_len);
	net_buf_add_mem(buf, data, remaining);

	return buf;
}

static struct net_buf *hci_ipc_acl_recv(uint8_t *data, size_t remaining)
{
	struct bt_hci_acl_hdr *hdr = (void *)data;
	struct net_buf *buf;

	if (remaining < sizeof(*hdr)) {
		LOG_ERR("Not enough data for ACL header");
		return NULL;
	}

	buf = bt_buf_get_tx(BT_BUF_ACL_OUT, K_NO_WAIT, hdr, sizeof(*hdr));
	if (buf) {
		data += sizeof(*hdr);
		remaining -= sizeof(*hdr);
	} else {
		LOG_ERR("No available ACL buffers!");
		return NULL;
	}

	if (remaining != sys_le16_to_cpu(hdr->len)) {
		LOG_ERR("ACL payload length is not correct");
		net_buf_unref(buf);
		return NULL;
	}

	if (remaining > net_buf_tailroom(buf)) {
		LOG_ERR("Not enough space in buffer");
		net_buf_unref(buf);
		return NULL;
	}

	LOG_DBG("len %u", remaining);
	net_buf_add_mem(buf, data, remaining);

	return buf;
}

static struct net_buf *hci_ipc_iso_recv(uint8_t *data, size_t remaining)
{
	struct bt_hci_iso_hdr *hdr = (void *)data;
	struct net_buf *buf;

	if (remaining < sizeof(*hdr)) {
		LOG_ERR("Not enough data for ISO header");
		return NULL;
	}

	buf = bt_buf_get_tx(BT_BUF_ISO_OUT, K_NO_WAIT, hdr, sizeof(*hdr));
	if (buf) {
		data += sizeof(*hdr);
		remaining -= sizeof(*hdr);
	} else {
		LOG_ERR("No available ISO buffers!");
		return NULL;
	}

	if (remaining != bt_iso_hdr_len(sys_le16_to_cpu(hdr->len))) {
		LOG_ERR("ISO payload length is not correct");
		net_buf_unref(buf);
		return NULL;
	}

	if (remaining > net_buf_tailroom(buf)) {
		LOG_ERR("Not enough space in buffer");
		net_buf_unref(buf);
		return NULL;
	}

	LOG_DBG("len %zu", remaining);
	net_buf_add_mem(buf, data, remaining);

	return buf;
}

static void hci_ipc_rx(uint8_t *data, size_t len)
{
	uint8_t pkt_indicator;
	struct net_buf *buf = NULL;
	size_t remaining = len;

	LOG_HEXDUMP_DBG(data, len, "IPC data:");

	pkt_indicator = *data++;
	remaining -= sizeof(pkt_indicator);

	switch (pkt_indicator) {
	case HCI_IPC_CMD:
		buf = hci_ipc_cmd_recv(data, remaining);
		break;

	case HCI_IPC_ACL:
		buf = hci_ipc_acl_recv(data, remaining);
		break;

	case HCI_IPC_ISO:
		buf = hci_ipc_iso_recv(data, remaining);
		break;

	default:
		LOG_ERR("Unknown HCI type %u", pkt_indicator);
		return;
	}

	if (buf) {
		k_fifo_put(&tx_queue, buf);

		LOG_HEXDUMP_DBG(buf->data, buf->len, "Final net buffer:");
	}
}

static void tx_thread(void *p1, void *p2, void *p3)
{
	while (1) {
		struct net_buf *buf;
		int err;

		/* Wait until a buffer is available */
		buf = k_fifo_get(&tx_queue, K_FOREVER);
		/* Pass buffer to the stack */
		err = bt_send(buf);
		if (err) {
			LOG_ERR("Unable to send (err %d)", err);
			net_buf_unref(buf);
		}

		/* Give other threads a chance to run if tx_queue keeps getting
		 * new data all the time.
		 */
		k_yield();
	}
}

static void hci_ipc_send(struct net_buf *buf, bool is_fatal_err)
{
	uint8_t retries = 0;
	int ret;

	LOG_DBG("buf %p type %u len %u", buf, buf->data[0], buf->len);

	LOG_HEXDUMP_DBG(buf->data, buf->len, "Final HCI buffer:");

	do {
		ret = ipc_service_send(&hci_ept, buf->data, buf->len);
		if (ret < 0) {
			retries++;
			if (retries > 10) {
				/* Default backend (rpmsg_virtio) has a timeout of 150ms. */
				LOG_WRN("IPC send has been blocked for 1.5 seconds.");
				retries = 0;
			}

			/* The function can be called by the application main thread,
			 * bt_ctlr_assert_handle and k_sys_fatal_error_handler. In case of a call by
			 * Bluetooth Controller assert handler or system fatal error handler the
			 * call can be from ISR context, hence there is no thread to yield. Besides
			 * that both handlers implement a policy to provide error information and
			 * stop the system in an infinite loop. The goal is to prevent any other
			 * damage to the system if one of such exceptional situations occur, hence
			 * call to k_yield is against it.
			 */
			if (is_fatal_err) {
				LOG_ERR("ipc_service_send error: %d", ret);
			} else {
				/* In the POSIX ARCH, code takes zero simulated time to execute,
				 * so busy wait loops become infinite loops, unless we
				 * force the loop to take a bit of time.
				 *
				 * This delay allows the IPC consumer to execute, thus making
				 * it possible to send more data over IPC afterwards.
				 */
				Z_SPIN_DELAY(500);
				k_yield();
			}
		}
	} while (ret < 0);

	LOG_INF("ipc_service_send sent %d/%u bytes", ret, buf->len);
	__ASSERT_NO_MSG(ret == buf->len);

	net_buf_unref(buf);
}

#if defined(CONFIG_BT_CTLR_ASSERT_HANDLER)
void bt_ctlr_assert_handle(char *file, uint32_t line)
{
	/* Disable interrupts, this is unrecoverable */
	(void)irq_lock();

#if defined(CONFIG_BT_HCI_VS_FATAL_ERROR)
	/* Generate an error event only when IPC service endpoint is already bound. */
	if (ipc_ept_ready) {
		/* Prepare vendor specific HCI debug event */
		struct net_buf *buf;

		buf = hci_vs_err_assert(file, line);
		if (buf != NULL) {
			/* Send the event over ipc */
			hci_ipc_send(buf, HCI_FATAL_ERR_MSG);
		} else {
			LOG_ERR("Can't create Fatal Error HCI event: %s at %d", __FILE__, __LINE__);
		}
	} else {
		LOG_ERR("IPC endpoint is not ready yet: %s at %d", __FILE__, __LINE__);
	}

	LOG_ERR("Halting system");

#else /* !CONFIG_BT_HCI_VS_FATAL_ERROR */
	LOG_ERR("Controller assert in: %s at %d", file, line);

#endif /* !CONFIG_BT_HCI_VS_FATAL_ERROR */

	/* Flush the logs before locking the CPU */
	LOG_PANIC();

	while (true) {
		k_cpu_idle();
	};

	CODE_UNREACHABLE;
}
#endif /* CONFIG_BT_CTLR_ASSERT_HANDLER */

#if defined(CONFIG_BT_HCI_VS_FATAL_ERROR)
void k_sys_fatal_error_handler(unsigned int reason, const struct arch_esf *esf)
{
	/* Disable interrupts, this is unrecoverable */
	(void)irq_lock();

	/* Generate an error event only when there is a stack frame and IPC service endpoint is
	 * already bound.
	 */
	if (esf != NULL && ipc_ept_ready) {
		/* Prepare vendor specific HCI debug event */
		struct net_buf *buf;

		buf = hci_vs_err_stack_frame(reason, esf);
		if (buf != NULL) {
			hci_ipc_send(buf, HCI_FATAL_ERR_MSG);
		} else {
			LOG_ERR("Can't create Fatal Error HCI event.\n");
		}
	}

	LOG_ERR("Halting system");

	/* Flush the logs before locking the CPU */
	LOG_PANIC();

	while (true) {
		k_cpu_idle();
	};

	CODE_UNREACHABLE;
}
#endif /* CONFIG_BT_HCI_VS_FATAL_ERROR */

static void hci_ept_bound(void *priv)
{
	k_sem_give(&ipc_bound_sem);
#if defined(CONFIG_BT_CTLR_ASSERT_HANDLER) || defined(CONFIG_BT_HCI_VS_FATAL_ERROR)
	ipc_ept_ready = true;
#endif /* CONFIG_BT_CTLR_ASSERT_HANDLER || CONFIG_BT_HCI_VS_FATAL_ERROR */
}

static void hci_ept_recv(const void *data, size_t len, void *priv)
{
	LOG_INF("Received message of %u bytes.", len);
	hci_ipc_rx((uint8_t *) data, len);
}

static struct ipc_ept_cfg hci_ept_cfg = {
	.name = "nrf_bt_hci",
	.cb = {
		.bound    = hci_ept_bound,
		.received = hci_ept_recv,
	},
};

int main(void)
{
	int err;
	const struct device *hci_ipc_instance =
		DEVICE_DT_GET(DT_CHOSEN(zephyr_bt_hci_ipc));

	/* incoming events and data from the controller */
	static K_FIFO_DEFINE(rx_queue);

	LOG_DBG("Start");

	/* Enable the raw interface, this will in turn open the HCI driver */
	bt_enable_raw(&rx_queue);

	/* Spawn the TX thread and start feeding commands and data to the
	 * controller
	 */
	k_thread_create(&tx_thread_data, tx_thread_stack,
			K_THREAD_STACK_SIZEOF(tx_thread_stack), tx_thread,
			NULL, NULL, NULL, K_PRIO_COOP(7), 0, K_NO_WAIT);
	k_thread_name_set(&tx_thread_data, "HCI ipc TX");

	/* Initialize IPC service instance and register endpoint. */
	err = ipc_service_open_instance(hci_ipc_instance);
	if (err < 0 && err != -EALREADY) {
		LOG_ERR("IPC service instance initialization failed: %d\n", err);
	}

	err = ipc_service_register_endpoint(hci_ipc_instance, &hci_ept, &hci_ept_cfg);
	if (err) {
		LOG_ERR("Registering endpoint failed with %d", err);
	}

	k_sem_take(&ipc_bound_sem, K_FOREVER);

	while (1) {
		struct net_buf *buf;

		buf = k_fifo_get(&rx_queue, K_FOREVER);
		hci_ipc_send(buf, HCI_REGULAR_MSG);
	}
	return 0;
}
```
